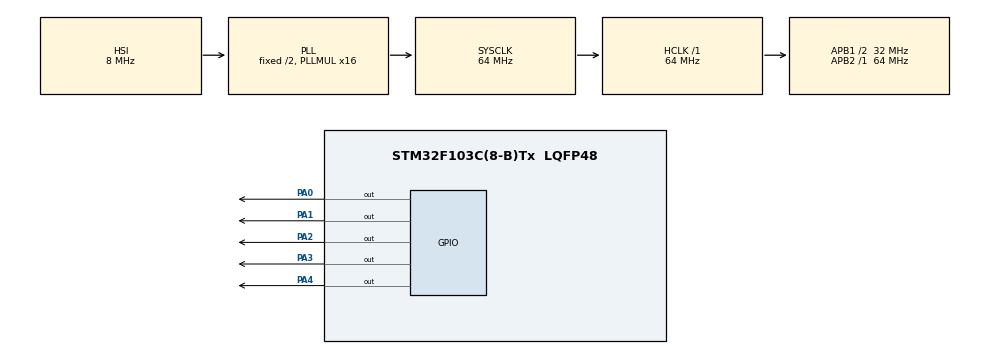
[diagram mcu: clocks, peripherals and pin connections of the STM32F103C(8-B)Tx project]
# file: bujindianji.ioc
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Mcu.Family=STM32F1
Mcu.Name=STM32F103C(8-B)Tx
Mcu.Package=LQFP48
NVIC.PriorityGroup=NVIC_PRIORITYGROUP_4
PA0-WKUP.GPIO_Speed=GPIO_SPEED_FREQ_MEDIUM
PA0-WKUP.Signal=GPIO_Output
PA1.GPIO_ModeDefaultOutputPP=GPIO_MODE_OUTPUT_PP
PA1.GPIO_PuPd=GPIO_NOPULL
PA1.GPIO_Speed=GPIO_SPEED_FREQ_MEDIUM
PA1.Signal=GPIO_Output
PA13.Mode=Serial_Wire
PA13.Signal=SYS_JTMS-SWDIO
PA14.Mode=Serial_Wire
PA14.Signal=SYS_JTCK-SWCLK
PA2.GPIO_ModeDefaultOutputPP=GPIO_MODE_OUTPUT_PP
PA2.GPIO_PuPd=GPIO_NOPULL
PA2.GPIO_Speed=GPIO_SPEED_FREQ_MEDIUM
PA2.PinState=GPIO_PIN_RESET
PA2.Signal=GPIO_Output
PA3.GPIO_ModeDefaultOutputPP=GPIO_MODE_OUTPUT_PP
PA3.GPIO_PuPd=GPIO_NOPULL
PA3.GPIO_Speed=GPIO_SPEED_FREQ_MEDIUM
PA3.PinState=GPIO_PIN_RESET
PA3.Signal=GPIO_Output
PA4.GPIO_ModeDefaultOutputPP=GPIO_MODE_OUTPUT_PP
PA4.GPIO_PuPd=GPIO_NOPULL
PA4.GPIO_Speed=GPIO_SPEED_FREQ_MEDIUM
PA4.PinState=GPIO_PIN_RESET
PA4.Signal=GPIO_Output
ProjectManager.HeapSize=0x200
ProjectManager.StackSize=0x400
ProjectManager.TargetToolchain=MDK-ARM V5.32
RCC.AHBFreq_Value=64000000
RCC.APB1CLKDivider=RCC_HCLK_DIV2
RCC.APB1Freq_Value=32000000
RCC.APB1TimFreq_Value=64000000
RCC.APB2Freq_Value=64000000
RCC.APB2TimFreq_Value=64000000
RCC.HCLKFreq_Value=64000000
RCC.PLLMUL=RCC_PLL_MUL16
RCC.SYSCLKFreq_VALUE=64000000
RCC.SYSCLKSource=RCC_SYSCLKSOURCE_PLLCLK
RCC.USBFreq_Value=64000000
board=custom

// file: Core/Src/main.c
/* USER CODE BEGIN Header */
/**
  ******************************************************************************
  * @file           : main.c
  * @brief          : Main program body
  ******************************************************************************
  * @attention
  *
  * Copyright (c) 2025 STMicroelectronics.
  * All rights reserved.
  *
  * This software is licensed under terms that can be found in the LICENSE file
  * in the root directory of this software component.
  * If no LICENSE file comes with this software, it is provided AS-IS.
  *
  ******************************************************************************
  */
/* USER CODE END Header */
#include "main.h"
#include "gpio.h"

/* USER CODE BEGIN Includes */
#include "bujin.h"
/* USER CODE END Includes */

void SystemClock_Config(void);

int main(void)
{

  /* MCU Configuration--------------------------------------------------------*/

  /* Reset of all peripherals, Initializes the Flash interface and the Systick. */
  HAL_Init();

  /* Configure the system clock */
  SystemClock_Config();

  /* Initialize all configured peripherals */
  MX_GPIO_Init();

  /* Infinite loop */
  /* USER CODE BEGIN WHILE */

  while (1)
  {
// 正转一圈，普通速度
	//StepMotor_RotateCircle(1, SPEED_NORMAL, STEP_MOTOR_DIR_FORWARD);

// 反转 180 度，快速
	//StepMotor_RotateAngle(180.0f, SPEED_FAST, STEP_MOTOR_DIR_BACKWARD);

// 转动 512 步，超快速度
	StepMotor_SetSpeed(SPEED_ULTRAFAST, STEP_MOTOR_DIR_FORWARD, 512);

    /* USER CODE END WHILE */

  }
}

void SystemClock_Config(void)
{
  RCC_OscInitTypeDef RCC_OscInitStruct = {0};
  RCC_ClkInitTypeDef RCC_ClkInitStruct = {0};

  /** Initializes the RCC Oscillators according to the specified parameters
  * in the RCC_OscInitTypeDef structure.
  */
  RCC_OscInitStruct.OscillatorType = RCC_OSCILLATORTYPE_HSI;
  RCC_OscInitStruct.HSIState = RCC_HSI_ON;
  RCC_OscInitStruct.HSICalibrationValue = RCC_HSICALIBRATION_DEFAULT;
  RCC_OscInitStruct.PLL.PLLState = RCC_PLL_ON;
  RCC_OscInitStruct.PLL.PLLSource = RCC_PLLSOURCE_HSI_DIV2;
  RCC_OscInitStruct.PLL.PLLMUL = RCC_PLL_MUL16;
  if (HAL_RCC_OscConfig(&RCC_OscInitStruct) != HAL_OK)
  {
    Error_Handler();
  }

  /** Initializes the CPU, AHB and APB buses clocks
  */
  RCC_ClkInitStruct.ClockType = RCC_CLOCKTYPE_HCLK|RCC_CLOCKTYPE_SYSCLK
                              |RCC_CLOCKTYPE_PCLK1|RCC_CLOCKTYPE_PCLK2;
  RCC_ClkInitStruct.SYSCLKSource = RCC_SYSCLKSOURCE_PLLCLK;
  RCC_ClkInitStruct.AHBCLKDivider = RCC_SYSCLK_DIV1;
  RCC_ClkInitStruct.APB1CLKDivider = RCC_HCLK_DIV2;
  RCC_ClkInitStruct.APB2CLKDivider = RCC_HCLK_DIV1;

  if (HAL_RCC_ClockConfig(&RCC_ClkInitStruct, FLASH_LATENCY_2) != HAL_OK)
  {
    Error_Handler();
  }
}

void Error_Handler(void)
{
  __disable_irq();
  while (1)
  {
  }
}
